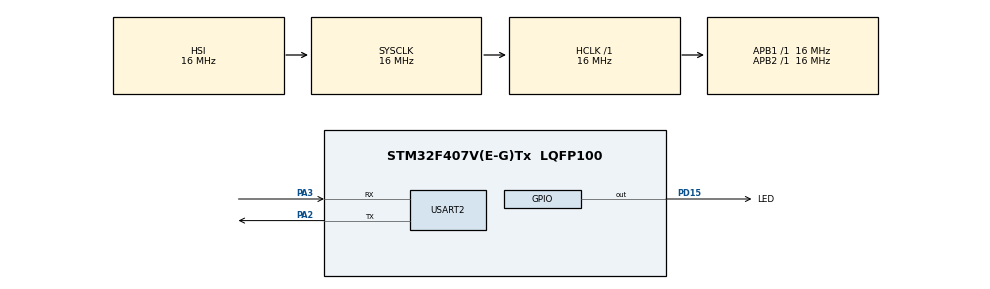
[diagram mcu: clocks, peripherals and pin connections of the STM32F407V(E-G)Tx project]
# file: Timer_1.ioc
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Mcu.Family=STM32F4
Mcu.Name=STM32F407V(E-G)Tx
Mcu.Package=LQFP100
NVIC.PriorityGroup=NVIC_PRIORITYGROUP_4
NVIC.TIM2_IRQn=true\:0\:0\:false\:false\:true\:true\:true\:true
PA2.Mode=Asynchronous
PA2.Signal=USART2_TX
PA3.Mode=Asynchronous
PA3.Signal=USART2_RX
PD15.GPIO_Label=LED
PD15.Signal=GPIO_Output
ProjectManager.HeapSize=0x200
ProjectManager.StackSize=0x400
ProjectManager.TargetToolchain=STM32CubeIDE
RCC.AHBFreq_Value=16000000
RCC.APB1Freq_Value=16000000
RCC.APB2Freq_Value=16000000
RCC.CortexFreq_Value=16000000
RCC.HSE_VALUE=25000000
RCC.HSI_VALUE=16000000
RCC.LSE_VALUE=32768
RCC.SYSCLKFreq_VALUE=16000000
RCC.VCOOutputFreq_Value=192000000
TIM2.Period=999
TIM2.Prescaler=7999
USART2.VirtualMode=VM_ASYNC
VP_TIM2_VS_ClockSourceINT.Mode=Internal
board=custom

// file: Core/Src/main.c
/* USER CODE BEGIN Header */
/**
  ******************************************************************************
  * @file           : main.c
  * @brief          : Main program body
  ******************************************************************************
  * @attention
  *
  * Copyright (c) 2026 STMicroelectronics.
  * All rights reserved.
  *
  * This software is licensed under terms that can be found in the LICENSE file
  * in the root directory of this software component.
  * If no LICENSE file comes with this software, it is provided AS-IS.
  *
  ******************************************************************************
  */
/* USER CODE END Header */
#include "main.h"

/* USER CODE BEGIN Includes */
#include <stdio.h>
/* USER CODE END Includes */

/* USER CODE BEGIN PD */
/* USER CODE BEGIN PD */
#define TICK_DELAY  1000   /* milliseconds between ticks */
/* USER CODE END PD */

TIM_HandleTypeDef htim2;

UART_HandleTypeDef huart2;

void SystemClock_Config(void);
static void MX_GPIO_Init(void);
static void MX_USART2_UART_Init(void);
static void MX_TIM2_Init(void);

/* USER CODE BEGIN 0 */
int _write(int fd, char *ptr, int len){
HAL_StatusTypeDef hstatus;

if (fd == 1 || fd == 2){
	hstatus = HAL_UART_Transmit(&huart2, (uint8_t*)ptr, len, HAL_MAX_DELAY);
	if(hstatus == HAL_OK)
		return 0;
	else
		return -1;
}

}
void HAL_TIM_PeriodElapsedCallback(TIM_HandleTypeDef *htim){
	HAL_GPIO_TogglePin(LED_GPIO_Port, LED_Pin);
}
/* USER CODE END 0 */

int main(void)
{

  /* MCU Configuration--------------------------------------------------------*/

  /* Reset of all peripherals, Initializes the Flash interface and the Systick. */
  HAL_Init();

  /* Configure the system clock */
  SystemClock_Config();

  /* Initialize all configured peripherals */
  MX_GPIO_Init();
  MX_USART2_UART_Init();
  MX_TIM2_Init();
  /* USER CODE BEGIN 2 */
  printf("Starting timer1\n");
  HAL_TIM_Base_Start_IT(&htim2);
  /* USER CODE END 2 */

  /* Infinite loop */
  /* USER CODE BEGIN WHILE */

  uint32_t now = 0, next_tick = TICK_DELAY;

  while (1)
  {
	  now = HAL_GetTick();

	      if (now >= next_tick) {
	          printf("Tick %lu\r\n", now / 1000);
	          next_tick = now + TICK_DELAY;
	      }
    /* USER CODE END WHILE */

  }
}

void SystemClock_Config(void)
{
  RCC_OscInitTypeDef RCC_OscInitStruct = {0};
  RCC_ClkInitTypeDef RCC_ClkInitStruct = {0};

  /** Configure the main internal regulator output voltage
  */
  __HAL_RCC_PWR_CLK_ENABLE();
  __HAL_PWR_VOLTAGESCALING_CONFIG(PWR_REGULATOR_VOLTAGE_SCALE1);

  /** Initializes the RCC Oscillators according to the specified parameters
  * in the RCC_OscInitTypeDef structure.
  */
  RCC_OscInitStruct.OscillatorType = RCC_OSCILLATORTYPE_HSI;
  RCC_OscInitStruct.HSIState = RCC_HSI_ON;
  RCC_OscInitStruct.HSICalibrationValue = RCC_HSICALIBRATION_DEFAULT;
  RCC_OscInitStruct.PLL.PLLState = RCC_PLL_NONE;
  if (HAL_RCC_OscConfig(&RCC_OscInitStruct) != HAL_OK)
  {
    Error_Handler();
  }

  /** Initializes the CPU, AHB and APB buses clocks
  */
  RCC_ClkInitStruct.ClockType = RCC_CLOCKTYPE_HCLK|RCC_CLOCKTYPE_SYSCLK
                              |RCC_CLOCKTYPE_PCLK1|RCC_CLOCKTYPE_PCLK2;
  RCC_ClkInitStruct.SYSCLKSource = RCC_SYSCLKSOURCE_HSI;
  RCC_ClkInitStruct.AHBCLKDivider = RCC_SYSCLK_DIV1;
  RCC_ClkInitStruct.APB1CLKDivider = RCC_HCLK_DIV1;
  RCC_ClkInitStruct.APB2CLKDivider = RCC_HCLK_DIV1;

  if (HAL_RCC_ClockConfig(&RCC_ClkInitStruct, FLASH_LATENCY_0) != HAL_OK)
  {
    Error_Handler();
  }
}

static void MX_TIM2_Init(void)
{

  TIM_ClockConfigTypeDef sClockSourceConfig = {0};
  TIM_MasterConfigTypeDef sMasterConfig = {0};

  htim2.Instance = TIM2;
  htim2.Init.Prescaler = 7999;
  htim2.Init.CounterMode = TIM_COUNTERMODE_UP;
  htim2.Init.Period = 999;
  htim2.Init.ClockDivision = TIM_CLOCKDIVISION_DIV1;
  htim2.Init.AutoReloadPreload = TIM_AUTORELOAD_PRELOAD_DISABLE;
  if (HAL_TIM_Base_Init(&htim2) != HAL_OK)
  {
    Error_Handler();
  }
  sClockSourceConfig.ClockSource = TIM_CLOCKSOURCE_INTERNAL;
  if (HAL_TIM_ConfigClockSource(&htim2, &sClockSourceConfig) != HAL_OK)
  {
    Error_Handler();
  }
  sMasterConfig.MasterOutputTrigger = TIM_TRGO_RESET;
  sMasterConfig.MasterSlaveMode = TIM_MASTERSLAVEMODE_DISABLE;
  if (HAL_TIMEx_MasterConfigSynchronization(&htim2, &sMasterConfig) != HAL_OK)
  {
    Error_Handler();
  }

}

static void MX_USART2_UART_Init(void)
{

  huart2.Instance = USART2;
  huart2.Init.BaudRate = 115200;
  huart2.Init.WordLength = UART_WORDLENGTH_8B;
  huart2.Init.StopBits = UART_STOPBITS_1;
  huart2.Init.Parity = UART_PARITY_NONE;
  huart2.Init.Mode = UART_MODE_TX_RX;
  huart2.Init.HwFlowCtl = UART_HWCONTROL_NONE;
  huart2.Init.OverSampling = UART_OVERSAMPLING_16;
  if (HAL_UART_Init(&huart2) != HAL_OK)
  {
    Error_Handler();
  }

}

static void MX_GPIO_Init(void)
{
  GPIO_InitTypeDef GPIO_InitStruct = {0};

  /* GPIO Ports Clock Enable */
  __HAL_RCC_GPIOA_CLK_ENABLE();
  __HAL_RCC_GPIOD_CLK_ENABLE();

  /*Configure GPIO pin Output Level */
  HAL_GPIO_WritePin(LED_GPIO_Port, LED_Pin, GPIO_PIN_RESET);

  /*Configure GPIO pin : LED_Pin */
  GPIO_InitStruct.Pin = LED_Pin;
  GPIO_InitStruct.Mode = GPIO_MODE_OUTPUT_PP;
  GPIO_InitStruct.Pull = GPIO_NOPULL;
  GPIO_InitStruct.Speed = GPIO_SPEED_FREQ_LOW;
  HAL_GPIO_Init(LED_GPIO_Port, &GPIO_InitStruct);

}

void Error_Handler(void)
{
  __disable_irq();
  while (1)
  {
  }
}
